# NSS_0_CFG_ALE register map
Vendor: Texas Instruments
Peripheral module from a debugger description file (folder 66AK2G0x_66AK2G1x).
Registers are 32-bit, access per field, reset values left out (the file's numbers can be read two ways) unless marked. A register's access mark holds for its fields unless they carry their own. Offsets are as the file gives them; lines under a group give offsets from that group; [hi:lo] are bit positions; {n}, {i} and the like mark numbered series; 'fields as' and 'values as' point back to an identical list; <NAME> marks a mode.

## NSS_0_CFG_ALE
0x00 ALE_IDVER ro
  [31:0] REV — TI internal data. Identifies revision of peripheral.
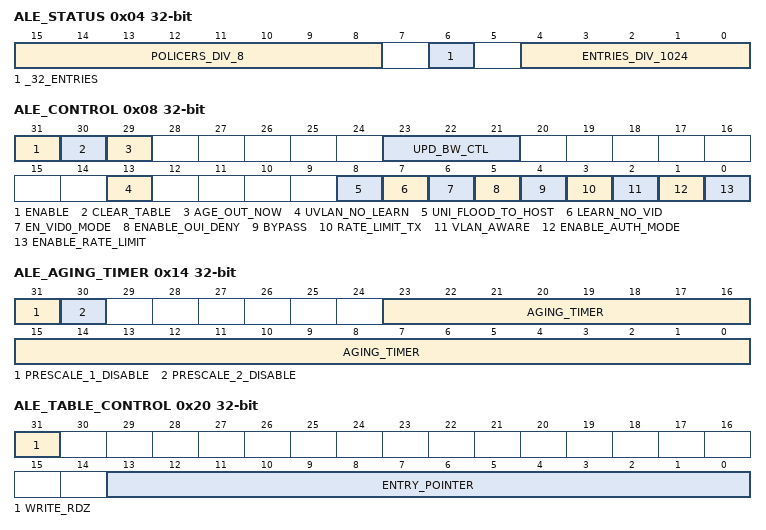
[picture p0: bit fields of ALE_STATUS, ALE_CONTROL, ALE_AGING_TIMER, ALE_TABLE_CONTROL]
0x04 ALE_STATUS ro
  [15:8] POLICERS_DIV_8 — This is the number of policers the ALE implements divided by 8 (a value of 4 indicates 32 policers total).
  [6] _32_ENTRIES — When set indicates that there are 32 entries in the ALE table.
  [4:0] ENTRIES_DIV_1024 — This is the number of table entries total divided by 1024. A value of 1 indicates 1024 table entries. A value of 8 indicates 8192 table entries. A value of 0 indicates less than 1024.
0x08 ALE_CONTROL
  [31] ENABLE rw — Enable ALE
  [30] CLEAR_TABLE rw — Clear ALE address table – Setting this bit causes the ALE hardware to write all table bit values to zero. Software must perform a clear table operation as part of the ALE setup/configuration process. Setting this bit causes all ALE accesses to be held up for 64 clocks while the clear is performed. Access to all ALE registers will be blocked (wait states) until the 64 clocks have completed. This bit cannot be read as one because the read is blocked until the clear table is completed at which time this bit is cleared to zero.
  [29] AGE_OUT_NOW rw — Age Out Address Table Now – Setting this bit causes the ALE hardware to remove (free up) any ageable table entry that does not have a set touch bit. This bit is cleared when the age out process has completed. This bit may be read. The age out process takes 4096 clocks best case (no ale packet processing during ageout) and 66550 clocks absolute worst case.
  [23:21] UPD_BW_CTL rw — The upd_bw_ctrl field allows for up to 8 times the rate in which adds, updates, touches, writes, and aging updates can occur
  [13] UVLAN_NO_LEARN rw — Unknown VLAN No Learn – when set this will prevent source addresses of unknown VLANIDs from being automatically added into the look up table if learning is enabled.
  [8] UNI_FLOOD_TO_HOST rw — Enable Port 0 Unicast Flood
  [7] LEARN_NO_VID rw
  [6] EN_VID0_MODE rw — Enable VLAN ID = 0 Mode
  [5] ENABLE_OUI_DENY rw — Enable OUI Deny Mode
  [4] BYPASS rw — ALE Bypass
  [3] RATE_LIMIT_TX rw — Rate Limit Transmit Mode
  [2] VLAN_AWARE rw — ALE VLAN Aware
  [1] ENABLE_AUTH_MODE rw — Enable MAC Authorization Mode – Mac authorization mode requires that all table entries be made by the host software. There are no learned address in authorization mode and the packet will be dropped if the source address is not found and the destination address is not an address with the super table entry bit set.
  [0] ENABLE_RATE_LIMIT rw — Enable Broadcast and Multicast Rate Limit
0x10 ALE_PRESCALE
  [19:0] PRESCALE rw — ALE Prescale – The input clock is divided by this value for use in the multicast/broadcast rate limiters. The minimum operating value is 0x10. The prescaler is off when the value is zero.
0x14 ALE_AGING_TIMER
  [31] PRESCALE_1_DISABLE rw — ALE Prescaler 1 Disable: When set, removes 1,000 from the auto aging multiplier.
  [30] PRESCALE_2_DISABLE rw — ALE Prescaler 2 Disable: When set, removes 1,000 from the auto aging multiplier.
  [23:0] AGING_TIMER rw — ALE Aging Timer: When non-zero, auto-aging is enabled. The ale_aging_timer value (minus 1) times 1,000,000 is the number of clock cycles after which auto-aging will automatically be initiated. If either prescale_1_disable or prescale_2_disable is set then the multiplier is 1,000 instead of 1,000,000. If both prescale_1_disable and prescale_2_disable are set then the multiplier is 1 instead of 1,000,000. Auto aging is initiated each time the count reaches zero. When the ale_aging_timer is zero, auto-aging is disabled (but software can still initiate aging by setting age_out_now). There is no auto-aging if ale_enable is zero or if clear_table is set or if age_out_now is set (while the events are occurring).
0x20 ALE_TABLE_CONTROL
  [31] WRITE_RDZ rw — Write Bit – This bit is always . Writing a 1 to this bit causes the three table word register values to be written to the entry_pointer location in the address table. Writing a 0 to this bit causes the three table word register values to be loaded from the entry_pointer location in the address table so that they may be subsequently read. A read of any ALE address location will be stalled until the read or write has completed.
  [13:0] ENTRY_POINTER rw — Table Entry Pointer - The ENTRY_POINTER contains the table entry value that will be read/written with accesses to the table word registers. The number of entries in the table determine the width of the entry pointer field (y). y = 9 for 1024 entries.
0x34 ALE_TABLE_WORD2
  [6:0] ENTRY_70_64 rw — Table entry bits 70 down to 64
0x38 ALE_TABLE_WORD1 rw
  [31:0] ENTRY_63_32 — Table Entry Bits 63:32
0x3C ALE_TABLE_WORD0 rw
  [31:0] ENTRY_31_0 — Table Entry Bits 31:0
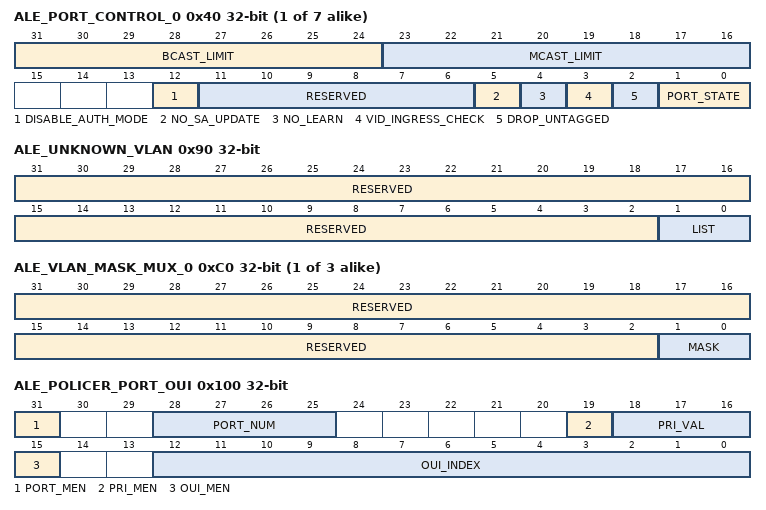
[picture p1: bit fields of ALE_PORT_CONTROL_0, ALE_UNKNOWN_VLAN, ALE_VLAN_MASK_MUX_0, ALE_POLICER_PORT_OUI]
{0x40+4i} ALE_PORT_CONTROL_{i} (i=0..6)
  [31:24] BCAST_LIMIT rw — Broadcast Packet Rate Limit Each prescale pulse loads this field into the port broadcast rate limit counter. The port counters are decremented with each packet received or transmitted depending on whether the mode is transmit or receive. If the counters decrement to zero, then further packets are rate limited until the next prescale pulse. Broadcast rate limiting is enabled by a non-zero value in this field.
  [23:16] MCAST_LIMIT rw — Multicast Packet Rate Limit Each prescale pulse loads this field into the port multicast rate limit counter. The port counters are decremented with each packet received or transmitted depending on whether the mode is transmit or receive. If the counters decrement to zero, then further packets are rate limited until the next prescale pulse. Multicast rate limiting is enabled by a non-zero value in this field.
  [12] DISABLE_AUTH_MODE rw — Disable MAC Authorization Mode When set, this bit disables MAC authorization mode for this port (when enable_auth_mode in ALE_Control is set).
  [11:6] RESERVED ro — Reads return 0.
  [5] NO_SA_UPDATE rw — No Source Address Update When set an ingress packet on this port will not cause a matching source address entry port number to be changed (to this port). When cleared, an ingress packet on this port will cause a matching source address entry port number to be changed to this port number (if it was previously a different port).
  [4] NO_LEARN rw — No Learn Mode When set the port is disabled from learning source addresses.
  [3] VID_INGRESS_CHECK rw — VLAN ID Ingress Check If VLAN found and the receive port is not a VLAN member then drop the packet.
  [2] DROP_UNTAGGED rw — Drop Untagged Packets - Drop non-VLAN tagged ingress packets
  [1:0] PORT_STATE rw
0x90 ALE_UNKNOWN_VLAN
  [31:2] RESERVED ro — Reads return 0 and writes have no effect.
  [1:0] LIST rw — Unknown VLAN Member List
0x94 ALE_UNKNOWN_UREG_MCAST_FLOOD
  [1:0] MASK rw — Unknown VLAN Multicast Flood Mask
0x98 ALE_UNKNOWN_REG_MCAST_FLOOD
  [1:0] MASK rw — Unknown VLAN Registered Multicast Flood Mask
0x9C ALE_FORCE_UNTAGGED_EGRESS
  [1:0] MASK rw — Force Untagged Egress Mask
{0xC0+4i} ALE_VLAN_MASK_MUX_{i} (i=0..2)
  [31:2] RESERVED ro — Reads return 0 and writes have no effect.
  [1:0] MASK rw — Force Untagged Egress Mask
0x100 ALE_POLICER_PORT_OUI
  [31] PORT_MEN rw — Enabled port match for the selected policing/classifier entry
  [28:25] PORT_NUM rw — If enabled, specifies the port address to match for the selected policing/classifier entry
  [19] PRI_MEN rw — Enabled frame priority match for the selected policing/classifier entry
  [18:16] PRI_VAL rw — If enabled, specifies the frame priority to match for the selected policing/classifier entry
  [15] OUI_MEN rw — Enabled frame OUI address match for the selected policing/classifier entry
  [12:0] OUI_INDEX rw — If enabled, specifies the ALE OUI address lookup table index to match for the selected policing/classifier entry
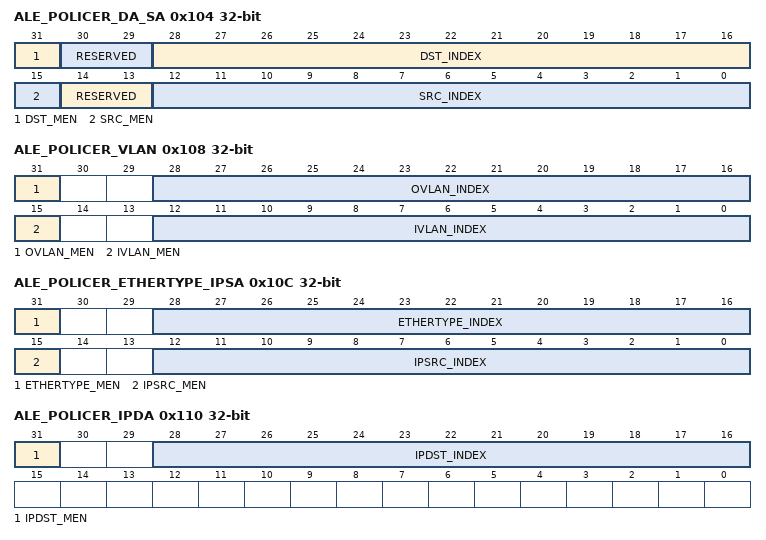
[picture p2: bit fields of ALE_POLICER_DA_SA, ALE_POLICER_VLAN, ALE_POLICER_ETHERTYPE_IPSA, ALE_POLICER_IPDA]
0x104 ALE_POLICER_DA_SA
  [31] DST_MEN rw — Enabled frame L2 destination address match for the selected policing/classifier entry
  [30:29] RESERVED ro — Reads return 0 and writes have no effect.
  [28:16] DST_INDEX rw — If enabled, specifies the ALE L2 destination address lookup table index to match for the selected policing/classifier entry
  [15] SRC_MEN rw — Enabled frame L2 source address match for the selected policing/classifier entry
  [14:13] RESERVED ro — Reads return 0 and writes have no effect.
  [12:0] SRC_INDEX rw — If enabled, specifies the ALE L2 source address lookup table index to match for the selected policing/classifier entry
0x108 ALE_POLICER_VLAN
  [31] OVLAN_MEN rw — Enabled frame Outer VLAN address match for the selected policing/classifier entry
  [28:16] OVLAN_INDEX rw — If enabled, specifies the ALE Outer VLAN address lookup table index to match for the selected policing/classifier entry
  [15] IVLAN_MEN rw — Enabled frame Inner VLAN address match for the selected policing/classifier entry
  [12:0] IVLAN_INDEX rw — If enabled, specifies the ALE Inner VLAN address lookup table index to match for the selected policing/classifier entry
0x10C ALE_POLICER_ETHERTYPE_IPSA
  [31] ETHERTYPE_MEN rw — Enabled frame Ether Type match for the selected policing/classifier entry
  [28:16] ETHERTYPE_INDEX rw — If enabled, specifies the ALE Ether Type lookup table index to match for the selected policing/classifier entry
  [15] IPSRC_MEN rw — Enabled frame IP Source address match for the selected policing/classifier entry
  [12:0] IPSRC_INDEX rw — If enabled, specifies the ALE IP Source address lookup table index to match for the selected policing/classifier entry
0x110 ALE_POLICER_IPDA
  [31] IPDST_MEN rw — Enabled frame IP Destination address match for the selected policing/classifier entry
  [28:16] IPDST_INDEX rw — If enabled, specifies the ALE IP Destination address lookup table index to match for the selected policing/classifier entry
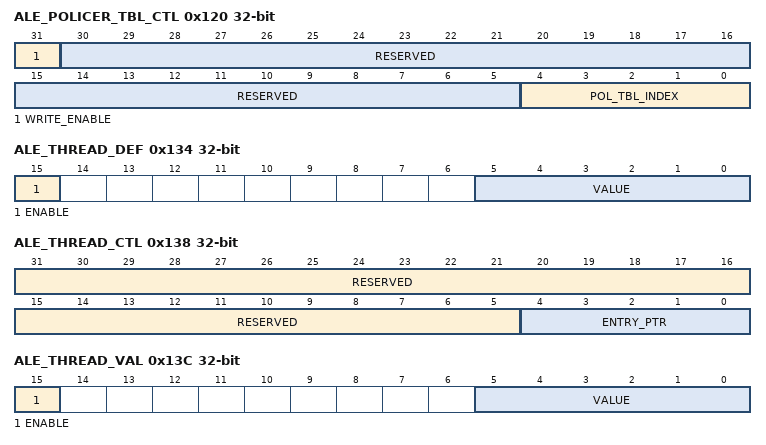
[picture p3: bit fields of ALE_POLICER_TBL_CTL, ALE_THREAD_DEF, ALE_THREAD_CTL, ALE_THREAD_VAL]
0x120 ALE_POLICER_TBL_CTL
  [31] WRITE_ENABLE rw — Setting this bit will write the POLICER_CFG0-7 to the pol_tbl_index selected policing/classifier entry
  [30:5] RESERVED ro — Reads return 0 and writes have no effect.
  [4:0] POL_TBL_INDEX rw — This field specifies the policing/classifier entry to be read or written
0x134 ALE_THREAD_DEF
  [15] ENABLE rw — This field is the read or written enable for the Default Thread ID. When set, the switch will use the def_thread_val for the default thread ID if no classifier is matched. If clear, the switch will generate its own thread ID based on port and priority if there is no classifier match.
  [5:0] VALUE rw — This field is the read or written default thread ID value that is used for host traffic.
0x138 ALE_THREAD_CTL
  [31:5] RESERVED ro — Reads return 0 and writes have no effect.
  [4:0] ENTRY_PTR rw — Policer Thread Entry Pointer. This field specificies the policer/classifier thread map entry to be read or written. This field is written with the policer/classifier number that will be read or written with a read or write to the ALE_Thread_Map register.
0x13C ALE_THREAD_VAL
  [15] ENABLE rw — This field is the read or written enable for the Thread ID. When set, the switch will use the thread_val for the particular classifier match. If clear, the switch will generate its own thread ID based on port and priority.
  [5:0] VALUE rw — This field is the read or written thread ID value that is used to map a classifier hit to thread ID for host traffic.
